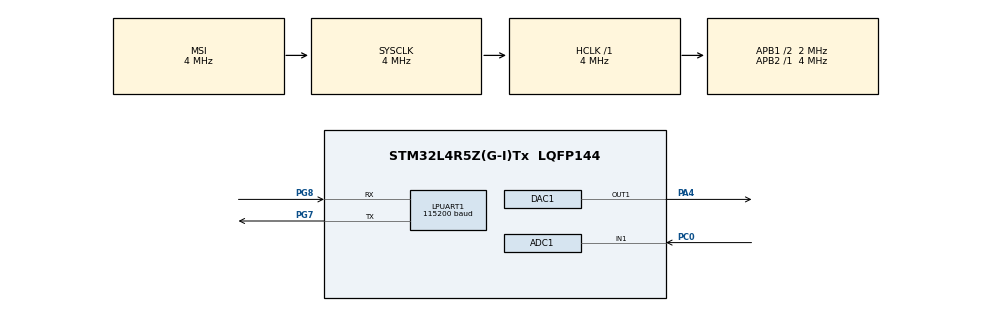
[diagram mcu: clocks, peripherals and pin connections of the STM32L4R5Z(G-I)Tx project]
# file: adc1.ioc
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ADC1.Channel-0\#ChannelRegularConversion=ADC_CHANNEL_1
ADC1.NbrOfConversion=1
ADC1.NbrOfConversionFlag=1
ADC1.OffsetNumber-0\#ChannelRegularConversion=ADC_OFFSET_NONE
ADC1.Rank-0\#ChannelRegularConversion=1
ADC1.Resolution=ADC_RESOLUTION_8B
ADC1.SamplingTime-0\#ChannelRegularConversion=ADC_SAMPLETIME_2CYCLES_5
ADC1.master=1
LPUART1.BaudRate=115200
LPUART1.WordLength=UART_WORDLENGTH_8B
Mcu.Family=STM32L4
Mcu.Name=STM32L4R5Z(G-I)Tx
Mcu.Package=LQFP144
NVIC.PriorityGroup=NVIC_PRIORITYGROUP_4
PA4.Signal=COMP_DAC11_group
PC0.Signal=ADCx_IN1
PG7.Mode=Asynchronous
PG7.Signal=LPUART1_TX
PG8.Mode=Asynchronous
PG8.Signal=LPUART1_RX
ProjectManager.HeapSize=0x200
ProjectManager.StackSize=0x400
ProjectManager.TargetToolchain=STM32CubeIDE
RCC.48MHZClocksFreq_Value=24000000
RCC.ADCFreq_Value=32000000
RCC.AHBFreq_Value=4000000
RCC.APB1CLKDivider=RCC_HCLK_DIV2
RCC.APB1Freq_Value=2000000
RCC.APB1TimFreq_Value=4000000
RCC.APB2Freq_Value=4000000
RCC.APB2TimFreq_Value=4000000
RCC.CortexFreq_Value=4000000
RCC.HCLKFreq_Value=4000000
RCC.HSE_VALUE=8000000
RCC.HSI48_VALUE=48000000
RCC.HSI_VALUE=16000000
RCC.MSI_VALUE=4000000
RCC.PLLMUL=RCC_PLL_MUL9
RCC.PLLSAI1N=16
RCC.PRESCALERUSB=RCC_USBCLKSOURCE_PLL_DIV1_5
RCC.SYSCLKFreq_VALUE=4000000
RCC.SYSCLKSourceVirtual=RCC_SYSCLKSOURCE_PLLCLK
RCC.USBFreq_Value=32000000
RCC.VCOOutputFreq_Value=32000000
SH.ADCx_IN1.0=ADC1_IN1,IN1-Single-Ended
SH.COMP_DAC11_group.0=DAC1_OUT1,DAC_OUT1
board=NUCLEO-L4R5ZI

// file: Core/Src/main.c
/* USER CODE BEGIN Header */
/**
  ******************************************************************************
  * @file           : main.c
  * @brief          : Main program body
  ******************************************************************************
  * @attention
  *
  * <h2><center>&copy; Copyright (c) 2020 STMicroelectronics.
  * All rights reserved.</center></h2>
  *
  * This software component is licensed by ST under BSD 3-Clause license,
  * the "License"; You may not use this file except in compliance with the
  * License. You may obtain a copy of the License at:
  *                        opensource.org/licenses/BSD-3-Clause
  *
  ******************************************************************************
  */
/* USER CODE END Header */

#include "main.h"

/* USER CODE BEGIN Includes */
#include<stdio.h>
#include<string.h>
/* USER CODE END Includes */

ADC_HandleTypeDef hadc1;

DAC_HandleTypeDef hdac1;

UART_HandleTypeDef hlpuart1;
UART_HandleTypeDef huart1;

void SystemClock_Config(void);
static void MX_GPIO_Init(void);
static void MX_ADC1_Init(void);
static void MX_LPUART1_UART_Init(void);
static void MX_DAC1_Init(void);

/* USER CODE BEGIN 0 */
uint32_t value;
uint8_t val[10];
/* USER CODE END 0 */

int main(void)
{

  /* MCU Configuration--------------------------------------------------------*/

  /* Reset of all peripherals, Initializes the Flash interface and the Systick. */
  HAL_Init();

  /* Configure the system clock */
  SystemClock_Config();

  /* Initialize all configured peripherals */
  MX_GPIO_Init();
  MX_ADC1_Init();
  MX_LPUART1_UART_Init();
  MX_DAC1_Init();

  /* Infinite loop */
  while (1)
  {

    /* USER CODE BEGIN 3 */
	  HAL_ADC_Start(&hadc1);
	 HAL_DAC_Start(&hdac1, DAC_CHANNEL_1);
	  if((HAL_ADC_PollForConversion(&hadc1, 2))==HAL_OK)
	  {
	  value=HAL_ADC_GetValue(&hadc1);
	  }
	  sprintf((char*)val,"%ld\r\n",value);
  HAL_UART_Transmit(&hlpuart1, val, sizeof(val), 5);
  HAL_DAC_SetValue(&hdac1, DAC_CHANNEL_1, DAC_ALIGN_8B_R, value);
  HAL_Delay(50);
  }
  /* USER CODE END 3 */
}

void SystemClock_Config(void)
{
  RCC_OscInitTypeDef RCC_OscInitStruct = {0};
  RCC_ClkInitTypeDef RCC_ClkInitStruct = {0};
  RCC_PeriphCLKInitTypeDef PeriphClkInit = {0};

  /** Configure the main internal regulator output voltage
  */
  if (HAL_PWREx_ControlVoltageScaling(PWR_REGULATOR_VOLTAGE_SCALE1) != HAL_OK)
  {
    Error_Handler();
  }
  /** Initializes the CPU, AHB and APB busses clocks
  */
  RCC_OscInitStruct.OscillatorType = RCC_OSCILLATORTYPE_MSI;
  RCC_OscInitStruct.MSIState = RCC_MSI_ON;
  RCC_OscInitStruct.MSICalibrationValue = 0;
  RCC_OscInitStruct.MSIClockRange = RCC_MSIRANGE_6;
  RCC_OscInitStruct.PLL.PLLState = RCC_PLL_NONE;
  if (HAL_RCC_OscConfig(&RCC_OscInitStruct) != HAL_OK)
  {
    Error_Handler();
  }
  /** Initializes the CPU, AHB and APB busses clocks
  */
  RCC_ClkInitStruct.ClockType = RCC_CLOCKTYPE_HCLK|RCC_CLOCKTYPE_SYSCLK
                              |RCC_CLOCKTYPE_PCLK1|RCC_CLOCKTYPE_PCLK2;
  RCC_ClkInitStruct.SYSCLKSource = RCC_SYSCLKSOURCE_MSI;
  RCC_ClkInitStruct.AHBCLKDivider = RCC_SYSCLK_DIV1;
  RCC_ClkInitStruct.APB1CLKDivider = RCC_HCLK_DIV2;
  RCC_ClkInitStruct.APB2CLKDivider = RCC_HCLK_DIV1;

  if (HAL_RCC_ClockConfig(&RCC_ClkInitStruct, FLASH_LATENCY_0) != HAL_OK)
  {
    Error_Handler();
  }
  PeriphClkInit.PeriphClockSelection = RCC_PERIPHCLK_LPUART1|RCC_PERIPHCLK_ADC;
  PeriphClkInit.Lpuart1ClockSelection = RCC_LPUART1CLKSOURCE_PCLK1;
  PeriphClkInit.AdcClockSelection = RCC_ADCCLKSOURCE_PLLSAI1;
  PeriphClkInit.PLLSAI1.PLLSAI1Source = RCC_PLLSOURCE_MSI;
  PeriphClkInit.PLLSAI1.PLLSAI1M = 1;
  PeriphClkInit.PLLSAI1.PLLSAI1N = 16;
  PeriphClkInit.PLLSAI1.PLLSAI1P = RCC_PLLP_DIV2;
  PeriphClkInit.PLLSAI1.PLLSAI1Q = RCC_PLLQ_DIV2;
  PeriphClkInit.PLLSAI1.PLLSAI1R = RCC_PLLR_DIV2;
  PeriphClkInit.PLLSAI1.PLLSAI1ClockOut = RCC_PLLSAI1_ADC1CLK;
  if (HAL_RCCEx_PeriphCLKConfig(&PeriphClkInit) != HAL_OK)
  {
    Error_Handler();
  }
}

static void MX_ADC1_Init(void)
{

  ADC_ChannelConfTypeDef sConfig = {0};

  /** Common config
  */
  hadc1.Instance = ADC1;
  hadc1.Init.ClockPrescaler = ADC_CLOCK_ASYNC_DIV1;
  hadc1.Init.Resolution = ADC_RESOLUTION_8B;
  hadc1.Init.DataAlign = ADC_DATAALIGN_RIGHT;
  hadc1.Init.ScanConvMode = ADC_SCAN_DISABLE;
  hadc1.Init.EOCSelection = ADC_EOC_SINGLE_CONV;
  hadc1.Init.LowPowerAutoWait = DISABLE;
  hadc1.Init.ContinuousConvMode = DISABLE;
  hadc1.Init.NbrOfConversion = 1;
  hadc1.Init.DiscontinuousConvMode = DISABLE;
  hadc1.Init.NbrOfDiscConversion = 1;
  hadc1.Init.ExternalTrigConv = ADC_SOFTWARE_START;
  hadc1.Init.ExternalTrigConvEdge = ADC_EXTERNALTRIGCONVEDGE_NONE;
  hadc1.Init.DMAContinuousRequests = DISABLE;
  hadc1.Init.Overrun = ADC_OVR_DATA_PRESERVED;
  hadc1.Init.OversamplingMode = DISABLE;
  if (HAL_ADC_Init(&hadc1) != HAL_OK)
  {
    Error_Handler();
  }
  /** Configure Regular Channel
  */
  sConfig.Channel = ADC_CHANNEL_1;
  sConfig.Rank = ADC_REGULAR_RANK_1;
  sConfig.SamplingTime = ADC_SAMPLETIME_2CYCLES_5;
  sConfig.SingleDiff = ADC_SINGLE_ENDED;
  sConfig.OffsetNumber = ADC_OFFSET_NONE;
  sConfig.Offset = 0;
  if (HAL_ADC_ConfigChannel(&hadc1, &sConfig) != HAL_OK)
  {
    Error_Handler();
  }

}

static void MX_DAC1_Init(void)
{

  DAC_ChannelConfTypeDef sConfig = {0};

  /** DAC Initialization
  */
  hdac1.Instance = DAC1;
  if (HAL_DAC_Init(&hdac1) != HAL_OK)
  {
    Error_Handler();
  }
  /** DAC channel OUT1 config
  */
  sConfig.DAC_SampleAndHold = DAC_SAMPLEANDHOLD_DISABLE;
  sConfig.DAC_Trigger = DAC_TRIGGER_NONE;
  sConfig.DAC_HighFrequency = DAC_HIGH_FREQUENCY_INTERFACE_MODE_DISABLE;
  sConfig.DAC_OutputBuffer = DAC_OUTPUTBUFFER_ENABLE;
  sConfig.DAC_ConnectOnChipPeripheral = DAC_CHIPCONNECT_DISABLE;
  sConfig.DAC_UserTrimming = DAC_TRIMMING_FACTORY;
  if (HAL_DAC_ConfigChannel(&hdac1, &sConfig, DAC_CHANNEL_1) != HAL_OK)
  {
    Error_Handler();
  }

}

static void MX_LPUART1_UART_Init(void)
{

  hlpuart1.Instance = LPUART1;
  hlpuart1.Init.BaudRate = 115200;
  hlpuart1.Init.WordLength = UART_WORDLENGTH_8B;
  hlpuart1.Init.StopBits = UART_STOPBITS_1;
  hlpuart1.Init.Parity = UART_PARITY_NONE;
  hlpuart1.Init.Mode = UART_MODE_TX_RX;
  hlpuart1.Init.HwFlowCtl = UART_HWCONTROL_NONE;
  hlpuart1.Init.OneBitSampling = UART_ONE_BIT_SAMPLE_DISABLE;
  hlpuart1.Init.ClockPrescaler = UART_PRESCALER_DIV1;
  hlpuart1.AdvancedInit.AdvFeatureInit = UART_ADVFEATURE_NO_INIT;
  hlpuart1.FifoMode = UART_FIFOMODE_DISABLE;
  if (HAL_UART_Init(&hlpuart1) != HAL_OK)
  {
    Error_Handler();
  }
  if (HAL_UARTEx_SetTxFifoThreshold(&hlpuart1, UART_TXFIFO_THRESHOLD_1_8) != HAL_OK)
  {
    Error_Handler();
  }
  if (HAL_UARTEx_SetRxFifoThreshold(&hlpuart1, UART_RXFIFO_THRESHOLD_1_8) != HAL_OK)
  {
    Error_Handler();
  }
  if (HAL_UARTEx_DisableFifoMode(&huart1) != HAL_OK)
  {
    Error_Handler();
  }

}

static void MX_GPIO_Init(void)
{

  /* GPIO Ports Clock Enable */
  __HAL_RCC_GPIOC_CLK_ENABLE();
  __HAL_RCC_GPIOA_CLK_ENABLE();
  __HAL_RCC_GPIOG_CLK_ENABLE();
  HAL_PWREx_EnableVddIO2();

}

void Error_Handler(void)
{
}

/************************ (C) COPYRIGHT STMicroelectronics *****END OF FILE****/
